# R7FA6M1AD register map
Vendor: Renesas; Series: RA6; File version: 1.2
CPU: CM4 r0p1, little endian, MPU, FPU, VTOR, 4 interrupt priority bits
Registers are 8-bit, read-write, reset 0x0 unless marked. A register's access mark holds for its fields unless they carry their own. Offsets are from the block's base; [hi:lo] are bit positions.

## DMA — DMAC Module Activation
Base 0x40005200
0x00 DMAST — DMA Module Activation Register
  [0] DMST — DMAC Operation Enable

## DTC — Data Transfer Controller
Base 0x40005400
0x00 DTCCR reset 0x8 — DTC Control Register
  [4] RRS — DTC Transfer Information Read Skip Enable.
0x04 DTCVBR 32-bit — DTC Vector Base Register
  [31:0] DTCVBR — DTC Vector Base Address.Note: A value cannot be set in the lower,order 10 bits. These bits are fixed to 0.
0x0C DTCST — DTC Module Start Register
  [0] DTCST — DTC Module Start
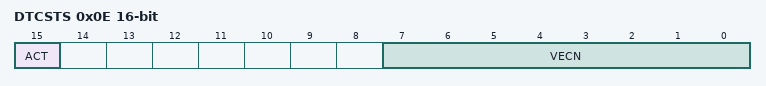
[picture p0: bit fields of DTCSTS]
0x0E DTCSTS 16-bit ro — DTC Status Register
  [15] ACT — DTC Active Flag
  [7:0] VECN — DTC,Activating Vector Number MonitoringThese bits indicate the vector number for the activating source when DTC transfer is in progress.The value is only valid if DTC transfer is in progress (the value of the ACT flag is 1)

## MMF — Memory Mirror Function
Base 0x40001000
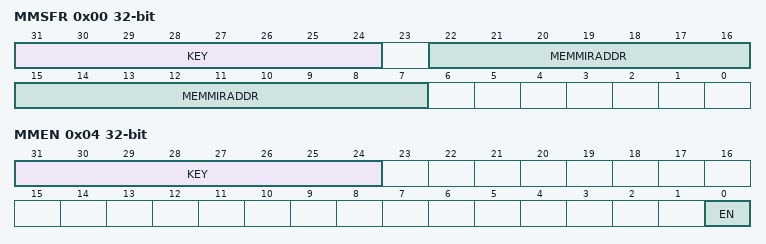
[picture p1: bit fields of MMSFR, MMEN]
0x00 MMSFR 32-bit — MemMirror Special Function Register
  [31:24] KEY wo — MMSFR Key Code
  [22:7] MEMMIRADDR — Specifies the memory mirror address.NOTE: A value cannot be set in the low,order 7 bits. These bits are fixed to 0.
0x04 MMEN 32-bit — MemMirror Enable Register
  [31:24] KEY wo — MMEN Key Code
  [0] EN — Memory Mirror Function Enable

## SRAM — SRAM Control
Base 0x40002000
0x00 PARIOAD — SRAM Parity Error Operation After Detection Register
  [0] OAD — Operation after Detection
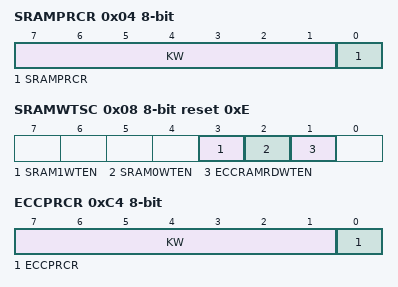
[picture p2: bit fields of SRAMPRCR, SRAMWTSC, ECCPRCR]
0x04 SRAMPRCR — SRAM Protection Register
  [7:1] KW wo — Write Key Code
  [0] SRAMPRCR — Register Write Control
0x08 SRAMWTSC reset 0xE — RAM Wait State Control Register
  [3] SRAM1WTEN — SRAM1 Wait Enable
  [2] SRAM0WTEN — SRAM0 Wait Enable
  [1] ECCRAMRDWTEN — ECCRAM Read wait enable
0xC0 ECCMODE — ECCRAM Operating Mode Control Register
  [1:0] ECCMOD — ECC Operating Mode Select
0xC1 ECC2STS — ECCRAM 2-Bit Error Status Register
  [0] ECC2ERR write-0-clears read-modifies — ECC 2-Bit Error Status
0xC2 ECC1STSEN — ECCRAM 1-Bit Error Information Update Enable Register
  [0] E1STSEN — ECC 1-Bit Error Information Update Enable
0xC3 ECC1STS — ECCRAM 1-Bit Error Status Register
  [0] ECC1ERR write-0-clears read-modifies — ECC 1-Bit Error Status
0xC4 ECCPRCR — ECCRAM Protection Register
  [7:1] KW wo — Write Key Code
  [0] ECCPRCR — ECCRAMETST Register Write Control
0xD4 ECCETST — ECC Test Control Register
  [0] TSTBYP — ECC Bypass Select
0xD8 ECCOAD — RAM ECC Error Operation After Detection Register
  [0] OAD — Operation after Detection

## FCACHE — Flash Cache
Base 0x4001C000
0x100 FCACHEE 16-bit — Flash Cache Enable Register
  [0] FCACHEEN — FCACHE Enable
0x104 FCACHEIV 16-bit — Flash Cache Invalidate Register
  [0] FCACHEIV write-1-sets read-modifies — FCACHE Invalidation
0x11C FLWT — Flash Wait Cycle Register
  [2:0] FLWT — Flash Wait Cycle

## MSTP — Module Stop Control B,C,D
Base 0x40047000
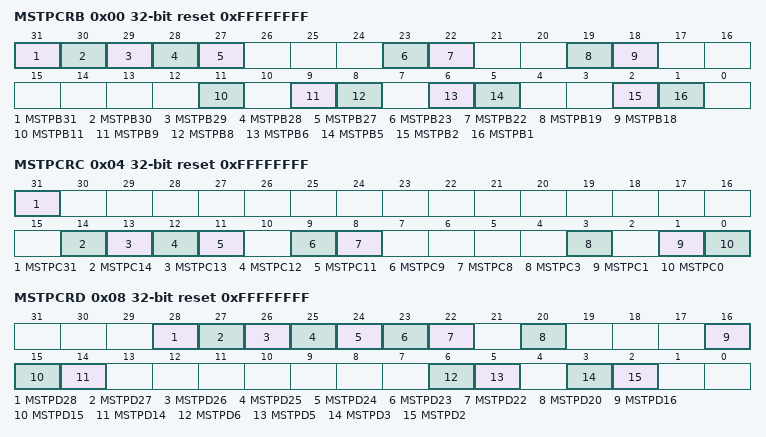
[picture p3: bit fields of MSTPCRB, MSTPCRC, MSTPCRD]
0x00 MSTPCRB 32-bit reset 0xFFFFFFFF — Module Stop Control Register B
  [31] MSTPB31 — Serial Communication Interface 0 Module Stop
  [30] MSTPB30 — Serial Communication Interface 1 Module Stop
  [29] MSTPB29 — Serial Communication Interface 2 Module Stop
  [28] MSTPB28 — Serial Communication Interface 3 Module Stop
  [27] MSTPB27 — Serial Communication Interface 4 Module Stop
  [23] MSTPB23 — Serial Communication Interface 8 Module Stop
  [22] MSTPB22 — Serial Communication Interface 9 Module Stop
  [19] MSTPB19 — Serial Peripheral Interface 0 Module Stop
  [18] MSTPB18 — Serial Peripheral Interface Module Stop
  [11] MSTPB11 — Universal Serial Bus 2.0 FS Interface Module Stop
  [9] MSTPB9 — I2C Bus Interface 0 Module Stop
  [8] MSTPB8 — I2C Bus Interface 1 Module Stop
  [6] MSTPB6 — Queued Serial Peripheral Interface Module Stop
  [5] MSTPB5 — IrDA Module Stop
  [2] MSTPB2 — Controller Area Network 0 Module Stop
  [1] MSTPB1 — Controller Area Network 1 Module Stop
0x04 MSTPCRC 32-bit reset 0xFFFFFFFF — Module Stop Control Register C
  [31] MSTPC31 — SCE7 Module Stop
  [14] MSTPC14 — Event Link Controller Module Stop
  [13] MSTPC13 — Data Operation Circuit Module Stop
  [12] MSTPC12 — Secure Digital Host IF/MultiMediaCard 0 Module Stop
  [11] MSTPC11 — Secure Digital Host IF/MultiMediaCard 1 Module Stop
  [9] MSTPC9 — Sampling Rate Converter Module Stop
  [8] MSTPC8 — Serial Sound Interface Enhanced (channel 0) Module Stop
  [3] MSTPC3 — Capacitive Touch Sensing Unit Module Stop
  [1] MSTPC1 — Cyclic Redundancy Check Calculator Module Stop
  [0] MSTPC0 — Clock Frequency Accuracy Measurement Circuit Module Stop
0x08 MSTPCRD 32-bit reset 0xFFFFFFFF — Module Stop Control Register D
  [28] MSTPD28 — High,Speed Analog Comparator 0 Module Stop
  [27] MSTPD27 — High,Speed Analog Comparator 1 Module Stop
  [26] MSTPD26 — High,Speed Analog Comparator 2 Module Stop
  [25] MSTPD25 — High,Speed Analog Comparator 3 Module Stop
  [24] MSTPD24 — High,Speed Analog Comparator 4 Module Stop
  [23] MSTPD23 — High,Speed Analog Comparator 5 Module Stop
  [22] MSTPD22 — Temperature Sensor Module Stop
  [20] MSTPD20 — 12-Bit D/A Converter Module Stop
  [16] MSTPD16 — 12-Bit A/D Converter 0 Module Stop
  [15] MSTPD15 — 12-Bit A/D Converter 1 Module Stop
  [14] MSTPD14 — Port Output Enable for GPT Module Stop
  [6] MSTPD6 — General PWM Timer 32_8 to 32_12 Module Stop
  [5] MSTPD5 — General PWM Timer 32EH0 to 32EH3 and 32E4 to 32E7 and PWM Delay Generation Circuit Module Stop
  [3] MSTPD3 — AGT0 Module Stop Note: AGT0 is in the module stop state when the count source is either of PCLKB, PCLKB/2 or PCLKB/8. In case the count source is sub,clock or LOCO, this bit should be set to 1 except when accessing the registers of AGT0.
  [2] MSTPD2 — AGT1 Module Stop Note: AGT1 is in the module stop state when the count source is either of PCLKB, PCLKB/2 or PCLKB/8. In case the count source is sub,clock or LOCO, this bit should be set to 1 except when accessing the registers of AGT1.
